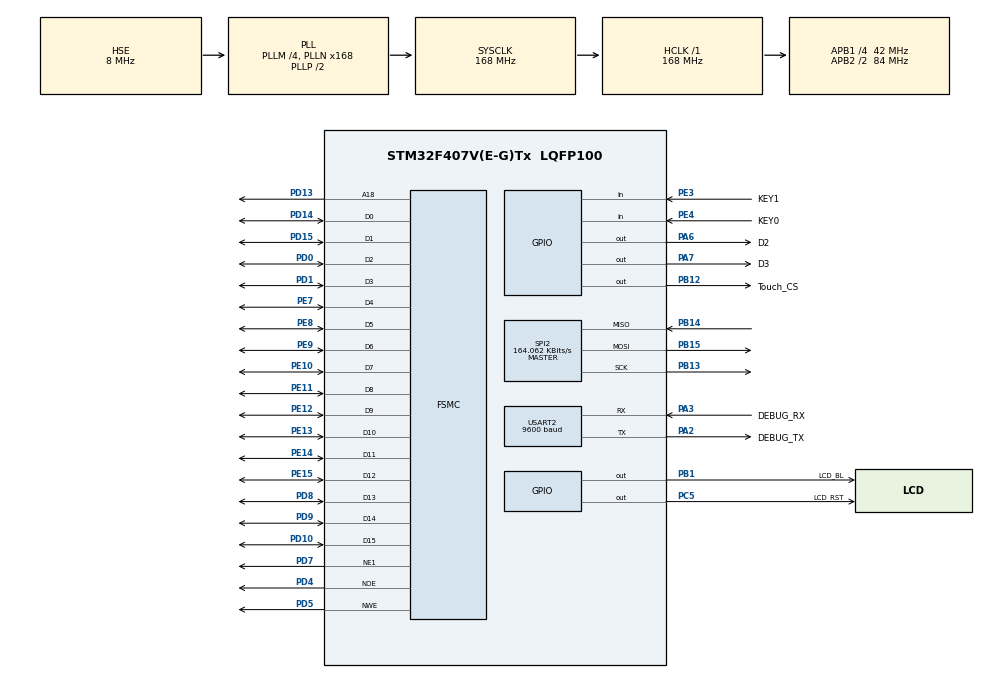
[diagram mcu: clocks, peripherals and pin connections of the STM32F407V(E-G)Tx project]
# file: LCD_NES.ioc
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FSMC.AddressSetupTime1=4
FSMC.BusTurnAroundDuration1=0
FSMC.DataSetupTime1=10
Mcu.Family=STM32F4
Mcu.Name=STM32F407V(E-G)Tx
Mcu.Package=LQFP100
NVIC.PriorityGroup=NVIC_PRIORITYGROUP_4
PA0-WKUP.Mode=SYS_WakeUp0
PA0-WKUP.Signal=SYS_WKUP
PA13.Mode=Serial_Wire
PA13.Signal=SYS_JTMS-SWDIO
PA14.Mode=Serial_Wire
PA14.Signal=SYS_JTCK-SWCLK
PA2.GPIO_Label=DEBUG_TX
PA2.Mode=Asynchronous
PA2.Signal=USART2_TX
PA3.GPIO_Label=DEBUG_RX
PA3.Mode=Asynchronous
PA3.Signal=USART2_RX
PA6.GPIO_Label=D2
PA6.GPIO_Speed=GPIO_SPEED_FREQ_VERY_HIGH
PA6.Signal=GPIO_Output
PA7.GPIO_Label=D3
PA7.GPIO_Speed=GPIO_SPEED_FREQ_VERY_HIGH
PA7.Signal=GPIO_Output
PB1.GPIO_Label=LCD_BL
PB1.GPIO_Speed=GPIO_SPEED_FREQ_VERY_HIGH
PB1.Signal=GPIO_Output
PB12.GPIO_Label=Touch_CS
PB12.GPIO_Speed=GPIO_SPEED_FREQ_VERY_HIGH
PB12.Signal=GPIO_Output
PB13.Mode=Full_Duplex_Master
PB13.Signal=SPI2_SCK
PB14.Mode=Full_Duplex_Master
PB14.Signal=SPI2_MISO
PB15.Mode=Full_Duplex_Master
PB15.Signal=SPI2_MOSI
PC14-OSC32_IN.Mode=LSE-External-Oscillator
PC14-OSC32_IN.Signal=RCC_OSC32_IN
PC15-OSC32_OUT.Mode=LSE-External-Oscillator
PC15-OSC32_OUT.Signal=RCC_OSC32_OUT
PC5.GPIO_Label=LCD_RST
PC5.GPIO_Speed=GPIO_SPEED_FREQ_VERY_HIGH
PC5.Signal=GPIO_Output
PD0.Mode=16b-d1
PD0.Signal=FSMC_D2
PD1.Mode=16b-d1
PD1.Signal=FSMC_D3
PD10.Mode=16b-d1
PD10.Signal=FSMC_D15
PD13.Mode=A18_1
PD13.Signal=FSMC_A18
PD14.Mode=16b-d1
PD14.Signal=FSMC_D0
PD15.Mode=16b-d1
PD15.Signal=FSMC_D1
PD4.Mode=Lcd1
PD4.Signal=FSMC_NOE
PD5.Mode=Lcd1
PD5.Signal=FSMC_NWE
PD7.Mode=NorPsramChipSelect1_1
PD7.Signal=FSMC_NE1
PD8.Mode=16b-d1
PD8.Signal=FSMC_D13
PD9.Mode=16b-d1
PD9.Signal=FSMC_D14
PE10.Mode=16b-d1
PE10.Signal=FSMC_D7
PE11.Mode=16b-d1
PE11.Signal=FSMC_D8
PE12.Mode=16b-d1
PE12.Signal=FSMC_D9
PE13.Mode=16b-d1
PE13.Signal=FSMC_D10
PE14.Mode=16b-d1
PE14.Signal=FSMC_D11
PE15.Mode=16b-d1
PE15.Signal=FSMC_D12
PE3.GPIO_Label=KEY1
PE3.Signal=GPIO_Input
PE4.GPIO_Label=KEY0
PE4.Signal=GPIO_Input
PE7.Mode=16b-d1
PE7.Signal=FSMC_D4
PE8.Mode=16b-d1
PE8.Signal=FSMC_D5
PE9.Mode=16b-d1
PE9.Signal=FSMC_D6
PH0-OSC_IN.Mode=HSE-External-Oscillator
PH0-OSC_IN.Signal=RCC_OSC_IN
PH1-OSC_OUT.Mode=HSE-External-Oscillator
PH1-OSC_OUT.Signal=RCC_OSC_OUT
ProjectManager.HeapSize=0x800
ProjectManager.StackSize=0x1000
ProjectManager.TargetToolchain=MDK-ARM V5
RCC.48MHZClocksFreq_Value=48000000
RCC.AHBFreq_Value=168000000
RCC.APB1CLKDivider=RCC_HCLK_DIV4
RCC.APB1Freq_Value=42000000
RCC.APB1TimFreq_Value=84000000
RCC.APB2CLKDivider=RCC_HCLK_DIV2
RCC.APB2Freq_Value=84000000
RCC.APB2TimFreq_Value=168000000
RCC.CortexFreq_Value=168000000
RCC.HCLKFreq_Value=168000000
RCC.HSE_VALUE=8000000
RCC.HSI_VALUE=16000000
RCC.PLLM=4
RCC.PLLN=168
RCC.PLLQ=7
RCC.PLLSourceVirtual=RCC_PLLSOURCE_HSE
RCC.SYSCLKFreq_VALUE=168000000
RCC.SYSCLKSource=RCC_SYSCLKSOURCE_PLLCLK
RCC.VCOOutputFreq_Value=336000000
SPI2.BaudRatePrescaler=SPI_BAUDRATEPRESCALER_256
SPI2.CalculateBaudRate=164.062 KBits/s
SPI2.Direction=SPI_DIRECTION_2LINES
SPI2.Mode=SPI_MODE_MASTER
SPI2.VirtualType=VM_MASTER
USART2.BaudRate=9600
USART2.VirtualMode=VM_ASYNC
VP_RTC_VS_RTC_Activate.Mode=RTC_Enabled
VP_RTC_VS_RTC_Calendar.Mode=RTC_Calendar
board=LCD_LittlevGL

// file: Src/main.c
/**
  ******************************************************************************
  * @file           : main.c
  * @brief          : Main program body
  ******************************************************************************
  ** This notice applies to any and all portions of this file
  * that are not between comment pairs USER CODE BEGIN and
  * USER CODE END. Other portions of this file, whether
  * inserted by the user or by software development tools
  * are owned by their respective copyright owners.
  *
  * COPYRIGHT(c) 2018 STMicroelectronics
  *
  * Redistribution and use in source and binary forms, with or without modification,
  * are permitted provided that the following conditions are met:
  *   1. Redistributions of source code must retain the above copyright notice,
  *      this list of conditions and the following disclaimer.
  *   2. Redistributions in binary form must reproduce the above copyright notice,
  *      this list of conditions and the following disclaimer in the documentation
  *      and/or other materials provided with the distribution.
  *   3. Neither the name of STMicroelectronics nor the names of its contributors
  *      may be used to endorse or promote products derived from this software
  *      without specific prior written permission.
  *
  * THIS SOFTWARE IS PROVIDED BY THE COPYRIGHT HOLDERS AND CONTRIBUTORS "AS IS"
  * AND ANY EXPRESS OR IMPLIED WARRANTIES, INCLUDING, BUT NOT LIMITED TO, THE
  * IMPLIED WARRANTIES OF MERCHANTABILITY AND FITNESS FOR A PARTICULAR PURPOSE ARE
  * DISCLAIMED. IN NO EVENT SHALL THE COPYRIGHT HOLDER OR CONTRIBUTORS BE LIABLE
  * FOR ANY DIRECT, INDIRECT, INCIDENTAL, SPECIAL, EXEMPLARY, OR CONSEQUENTIAL
  * DAMAGES (INCLUDING, BUT NOT LIMITED TO, PROCUREMENT OF SUBSTITUTE GOODS OR
  * SERVICES; LOSS OF USE, DATA, OR PROFITS; OR BUSINESS INTERRUPTION) HOWEVER
  * CAUSED AND ON ANY THEORY OF LIABILITY, WHETHER IN CONTRACT, STRICT LIABILITY,
  * OR TORT (INCLUDING NEGLIGENCE OR OTHERWISE) ARISING IN ANY WAY OUT OF THE USE
  * OF THIS SOFTWARE, EVEN IF ADVISED OF THE POSSIBILITY OF SUCH DAMAGE.
  *
  ******************************************************************************
  */
#include "main.h"
#include "stm32f4xx_hal.h"
#include "rtc.h"
#include "spi.h"
#include "usart.h"
#include "gpio.h"
#include "fsmc.h"

/* USER CODE BEGIN Includes */
#include "bsp_lcd.h"
#include "stdlib.h"
#include "InfoNES.h"
/* USER CODE END Includes */

/* USER CODE BEGIN PV */
/* Private variables ---------------------------------------------------------*/
extern const unsigned char _acContra[];
/* USER CODE END PV */

void SystemClock_Config(void);

/* USER CODE BEGIN PFP */
/* Private function prototypes -----------------------------------------------*/
extern void nesStart(void);
/* USER CODE END PFP */

int main(void)
{

  /* MCU Configuration----------------------------------------------------------*/

  /* Reset of all peripherals, Initializes the Flash interface and the Systick. */
  HAL_Init();

  /* Configure the system clock */
  SystemClock_Config();

  /* Initialize all configured peripherals */
  MX_GPIO_Init();
  MX_USART2_UART_Init();
  MX_FSMC_Init();
  MX_SPI2_Init();
  MX_RTC_Init();
  /* USER CODE BEGIN 2 */
		Lcd_Initialize();
  	//然后开始执行模拟器
	WorkFrame=(WORD*)malloc(240*256*2); //为显示一帧画面的数组申请内存空间
	if( 0 !=InfoNES_Load( (const char *)_acContra) ) //如果加载魂斗罗游戏失败则死循环
	{
		while(1){}
	}else
	{ //加载游戏成功则开始运行游戏模拟器
		InfoNES_Main();
	}
  /* USER CODE END 2 */

  /* Infinite loop */
  while (1)
  {

  }

}

void SystemClock_Config(void)
{

  RCC_OscInitTypeDef RCC_OscInitStruct;
  RCC_ClkInitTypeDef RCC_ClkInitStruct;
  RCC_PeriphCLKInitTypeDef PeriphClkInitStruct;

    /**Configure the main internal regulator output voltage
    */
  __HAL_RCC_PWR_CLK_ENABLE();

  __HAL_PWR_VOLTAGESCALING_CONFIG(PWR_REGULATOR_VOLTAGE_SCALE1);

    /**Initializes the CPU, AHB and APB busses clocks
    */
  RCC_OscInitStruct.OscillatorType = RCC_OSCILLATORTYPE_LSI|RCC_OSCILLATORTYPE_HSE;
  RCC_OscInitStruct.HSEState = RCC_HSE_ON;
  RCC_OscInitStruct.LSIState = RCC_LSI_ON;
  RCC_OscInitStruct.PLL.PLLState = RCC_PLL_ON;
  RCC_OscInitStruct.PLL.PLLSource = RCC_PLLSOURCE_HSE;
  RCC_OscInitStruct.PLL.PLLM = 4;
  RCC_OscInitStruct.PLL.PLLN = 168;
  RCC_OscInitStruct.PLL.PLLP = RCC_PLLP_DIV2;
  RCC_OscInitStruct.PLL.PLLQ = 7;
  if (HAL_RCC_OscConfig(&RCC_OscInitStruct) != HAL_OK)
  {
    _Error_Handler(__FILE__, __LINE__);
  }

    /**Initializes the CPU, AHB and APB busses clocks
    */
  RCC_ClkInitStruct.ClockType = RCC_CLOCKTYPE_HCLK|RCC_CLOCKTYPE_SYSCLK
                              |RCC_CLOCKTYPE_PCLK1|RCC_CLOCKTYPE_PCLK2;
  RCC_ClkInitStruct.SYSCLKSource = RCC_SYSCLKSOURCE_PLLCLK;
  RCC_ClkInitStruct.AHBCLKDivider = RCC_SYSCLK_DIV1;
  RCC_ClkInitStruct.APB1CLKDivider = RCC_HCLK_DIV4;
  RCC_ClkInitStruct.APB2CLKDivider = RCC_HCLK_DIV2;

  if (HAL_RCC_ClockConfig(&RCC_ClkInitStruct, FLASH_LATENCY_5) != HAL_OK)
  {
    _Error_Handler(__FILE__, __LINE__);
  }

  PeriphClkInitStruct.PeriphClockSelection = RCC_PERIPHCLK_RTC;
  PeriphClkInitStruct.RTCClockSelection = RCC_RTCCLKSOURCE_LSI;
  if (HAL_RCCEx_PeriphCLKConfig(&PeriphClkInitStruct) != HAL_OK)
  {
    _Error_Handler(__FILE__, __LINE__);
  }

    /**Configure the Systick interrupt time
    */
  HAL_SYSTICK_Config(HAL_RCC_GetHCLKFreq()/1000);

    /**Configure the Systick
    */
  HAL_SYSTICK_CLKSourceConfig(SYSTICK_CLKSOURCE_HCLK);

  /* SysTick_IRQn interrupt configuration */
  HAL_NVIC_SetPriority(SysTick_IRQn, 0, 0);
}

void _Error_Handler(char *file, int line)
{
  while(1)
  {
  }
}

/************************ (C) COPYRIGHT STMicroelectronics *****END OF FILE****/
